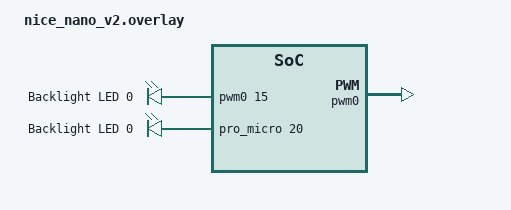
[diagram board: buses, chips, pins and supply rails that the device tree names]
#include "../scylla.dtsi"


&pwm0 {
	status = "okay";
	ch0-pin = <15>;
	/* ch0-inverted; */
};


/ {
backlight: pwmleds {
		   compatible = "pwm-leds";
		   label = "Backlight LEDs";
		   pwm_led_0 {
			   pwms = <&pwm0 15>;
			   label = "Backlight LED 0";
		   };
	   };
};


/ {
	chosen {
		zmk,backlight = &backlight;
	};
};
/ {
backlight: gpioleds {
		   compatible = "gpio-leds";
		   label = "Backlight LEDs";
		   gpio_led_0 {
			   gpios = <&pro_micro 20 GPIO_ACTIVE_HIGH>;
			   label = "Backlight LED 0";
		   };
	   };
};

};
